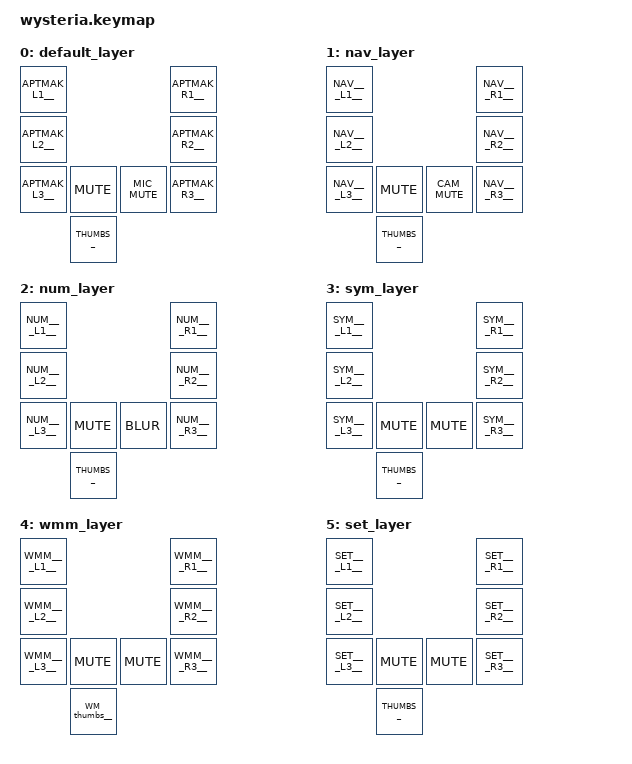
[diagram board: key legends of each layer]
#include <behaviors.dtsi>
#include <dt-bindings/zmk/keys.h>
#include "wrappers.h"
#include <dt-bindings/zmk/pointing.h>
#include <dt-bindings/zmk/bt.h>
#include <dt-bindings/zmk/outputs.h>

#include "secrets.keymap"

&nice_view_spi {
        cs-gpios = <&pro_micro 0 GPIO_ACTIVE_HIGH>;
};

#define COMBO(NAME, TERM, BINDINGS, KEYPOS) \
      combo_##NAME { \
          timeout-ms = <TERM>; \
          bindings = <BINDINGS>; \
          key-positions = <KEYPOS>; \
          layers = <0>; \
          slow-release; \
        };

/* #define U_MOUSE_SCROLL_MAX 200      // 10

#undef SCROLL_UP
#undef SCROLL_DOWN
#undef SCROLL_LEFT
#undef SCROLL_RIGHT
#define SCROLL_UP SCROLL_VERT(U_MOUSE_SCROLL_MAX)
#define SCROLL_DOWN SCROLL_VERT(-U_MOUSE_SCROLL_MAX)
#define SCROLL_LEFT SCROLL_HOR(-U_MOUSE_SCROLL_MAX)
#define SCROLL_RIGHT SCROLL_HOR(U_MOUSE_SCROLL_MAX)

*/

/* #define MACRO(NAME, BINDINGS) \ */
/*     macro_##NAME: macro_##NAME { \ */
/*                          compatible = "zmk,behavior-macro"; \ */
/*                          label = "ZM_my_macro"; \ */
/*                          #binding-cells = <0>; \ */
/*                          wait-ms = <30>; \ */
/*                          tap-ms = <40>; \ */
/*                          bindings = <BINDINGS>; \ */
/*                      }; */

&sk {
    quick-release;
    release-after-ms = <350>;
};
&sl {
    release-after-ms = <250>;
};


/ {
    behaviors {
        hm: homerow_mods {
            compatible = "zmk,behavior-hold-tap";
            label = "HOMEROW_MODS";
            #binding-cells = <2>;
            tapping-term-ms = <200>;
            quick-tap-ms = <0>;
            require-prior-idle-ms = <125>;
            flavor = "tap-preferred";
            bindings = <&kp>, <&kp>;
        };
      skq: sticky_key_quick_release {
        compatible = "zmk,behavior-sticky-key";
        label = "STICKY_KEY_QUICK_RELEASE";
        #binding-cells = <1>;
        bindings = <&kp>;
        release-after-ms = <250>;
        quick-release;
        ignore-modifiers;
      };
      wd_bspc_del: word_backspace_delete {
            compatible = "zmk,behavior-mod-morph";
            label = "WD_BACKSPACE_DELETE";
            #binding-cells = <0>;
            bindings = <&kp LA(BACKSPACE)>, <&kp LA(DELETE)>;
            mods = <(MOD_LSFT|MOD_RSFT)>;
        };
      bspc_del: backspace_delete {
            compatible = "zmk,behavior-mod-morph";
            label = "BACKSPACE_DELETE";
            #binding-cells = <0>;
            bindings = <&kp BACKSPACE>, <&kp DELETE>;
            mods = <(MOD_LSFT|MOD_RSFT)>;
        };
      dot: dot_colon {
            compatible = "zmk,behavior-mod-morph";
            label = "DOT_COLON";
            #binding-cells = <0>;
            bindings = <&kp DOT>, <&kp COLON>;
            mods = <(MOD_LSFT|MOD_RSFT)>;
            keep-mods = <(MOD_LSFT|MOD_RSFT)>;
        };
      comma: comma_scolon {
            compatible = "zmk,behavior-mod-morph";
            label = "COMMA_SCOLON";
            #binding-cells = <0>;
            bindings = <&kp COMMA>, <&kp SEMICOLON>;
            mods = <(MOD_LSFT|MOD_RSFT)>;
        };
      swap: swap_win {
            compatible = "zmk,behavior-tri-state";
            label = "SWAPPER";
            #binding-cells = <0>;
            bindings = <&kt LGUI>, <&kp TAB>, <&kt LGUI>;
            ignored-key-positions = <13>; // 13 corresponds to QWERTY F, which is my left shift
        };
      swap_app: swap_app_win {
            compatible = "zmk,behavior-tri-state";
            label = "SWAP_APP";
            #binding-cells = <0>;
            bindings = <&kt LGUI>, <&kp GRAVE>, <&kt LGUI>;
            ignored-key-positions = <13>; // 13 corresponds to QWERTY F, which is my left shift
        };
      rot_kp: behavior_sensor_rotate_kp {
            compatible = "zmk,behavior-sensor-rotate-var";
            label = "ENC_KP";
            #sensor-binding-cells = <2>;
            bindings = <&kp>, <&kp>;
        };
      rot_mwh: behavior_sensor_rotate_mwh {
            compatible = "zmk,behavior-sensor-rotate-var";
            label = "ENC_MOUSE";
            #sensor-binding-cells = <2>;
            bindings = <&msc>, <&msc>;
            tap-ms = <20>;
        };

    };

/*  0  1  2  3  4         5  6  7  8  9 */
/* 10 11 12 13 14        15 16 17 18 19 */
/* 20 21 22 23 24 25  26 27 28 29 30 31 */
/*          32 33 34  35 36 37          */

    combos {
          compatible = "zmk,combos";

            COMBO(x, 50, &kp X, 28 29)
            COMBO(z, 50, &kp Z, 22 23)
            COMBO(q, 50, &kp Q, 2 3)
            COMBO(lbkt, 50, &kp LBKT, 3 13)
            COMBO(rbkt, 50, &kp RBKT, 6 16)
            COMBO(lpar, 50, &kp LPAR, 2 12)
            COMBO(rpar, 50, &kp RPAR, 7 17)
            COMBO(caps_word_l, 50, &caps_word, 13 14)
            COMBO(caps_word_r, 50, &caps_word, 15 16)
            COMBO(lshift, 25, &sk LSHFT, 12 13)
            COMBO(rshift, 25, &sk RSHFT, 16 17)
            COMBO(emdash, 25, &kp RA(MINUS), 30 31)
            COMBO(bksp, 25, &bspc_del, 3 4)
            COMBO(ent, 25, &kp RET, 5 6)
            COMBO(htor, 50, &htor, 10 13)
            COMBO(dssr, 50, &dssr, 11 23)
            COMBO(pfv, 50, &pfv, 3 27)
            COMBO(ltab, 50, &kp TAB, 33 34)
            COMBO(rtab, 50, &kp TAB, 35 36)
    };

    conditional_layers {
        compatible = "zmk,conditional-layers";
        settings {
            if-layers = <2 4>;
            then-layer = <5>;
        };
    };

    macros {
        ZMK_MACRO(lock,
                wait-ms = <20>;
                tap-ms = <20>;
                bindings
                    = <&macro_press    &kp LGUI &kp LCTRL>
                    , <&macro_tap      &kp Q>
                    , <&macro_release  &kp LGUI &kp LCTRL>
                    , <&macro_wait_time 100>
                    , <&macro_tap      &none &kp ESC>;
                )
        ZMK_MACRO(nrc,
                wait-ms = <20>;
                tap-ms = <20>;
                bindings
                    = <&macro_press    &kp LSHFT>
                    , <&macro_tap      &kp N &kp R &kp C>
                    , <&macro_release  &kp LSHFT>;
                )
        ZMK_MACRO(mne,
                wait-ms = <20>;
                tap-ms = <20>;
                bindings
                    = <&macro_press    &kp LSHFT>
                    , <&macro_tap      &kp M &kp E &kp A &kp L>
                    , <&macro_release  &kp LSHFT>;
                )
        ZMK_MACRO(screenshot,
                wait-ms = <5>;
                tap-ms = <5>;
                bindings
                    = <&macro_press    &kp LSHFT &kp LGUI>
                    , <&macro_tap      &kp N5>
                    , <&macro_release  &kp LSHFT &kp LGUI>;
                )
        ZMK_MACRO(htor,
                wait-ms = <5>;
                tap-ms = <5>;
                bindings
                    = <&macro_press    &kp LSHFT>
                    , <&macro_tap      &kp H>
                    , <&macro_release  &kp LSHFT>
                    , <&macro_tap      &kp N2>
                    , <&macro_press    &kp LSHFT>
                    , <&macro_tap      &kp R>
                    , <&macro_release  &kp LSHFT>;
                )
        ZMK_MACRO(pfv,
                wait-ms = <5>;
                tap-ms = <5>;
                bindings
                    = <&macro_press    &kp LSHFT>
                    , <&macro_tap      &kp P>
                    , <&macro_release  &kp LSHFT>
                    , <&macro_tap      &kp F>
                    , <&macro_press    &kp LSHFT>
                    , <&macro_tap      &kp V>
                    , <&macro_release  &kp LSHFT>;
                )
        ZMK_MACRO(dssr,
                wait-ms = <5>;
                tap-ms = <5>;
                bindings
                    = <&macro_press    &kp LSHFT>
                    , <&macro_tap      &kp S &kp R>
                    , <&macro_release  &kp LSHFT>
                    , <&macro_tap      &kp FSLH>
                    , <&macro_press    &kp LSHFT>
                    , <&macro_tap      &kp D &kp S>
                    , <&macro_release  &kp LSHFT>;
                )
        ZMK_MACRO(pass,
                wait-ms = <5>;
                tap-ms = <5>;
                bindings
                    = <&macro_tap      SECRET_ONE>;
                )
        ZMK_MACRO(name,
                wait-ms = <5>;
                tap-ms = <5>;
                bindings
                    = SECRET_SIX;
                )
        ZMK_MACRO(work_email,
                wait-ms = <5>;
                tap-ms = <5>;
                bindings
                    = <&macro_tap SECRET_SEVEN>;
                )
        ZMK_MACRO(email,
                wait-ms = <5>;
                tap-ms = <5>;
                bindings
                    = <&macro_tap SECRET_TWO>;
                )
        ZMK_MACRO(phone,
                wait-ms = <5>;
                tap-ms = <5>;
                bindings
                    = <&macro_tap SECRET_THREE>;
                )
        ZMK_MACRO(so_phone,
                wait-ms = <5>;
                tap-ms = <5>;
                bindings
                    = <&macro_tap SECRET_FIVE>;
                )
        ZMK_MACRO(so_email,
                wait-ms = <5>;
                tap-ms = <5>;
                bindings
                    = <&macro_tap SECRET_FOUR>;
                )
    };

/*  0  1  2  3  4         5  6  7  8  9 */
/* 10 11 12 13 14        15 16 17 18 19 */
/* 20 21 22 23 24 25  26 27 28 29 30 31 */
/*          32 33 34  35 36 37          */

    leader_sequences {
        compatible = "zmk,leader-sequences";
        seq_pass {
            key-positions = <12 13>;
            bindings = <&pass>;
        };
        seq_name {
                key-positions = <13>;
                bindings = <&name>;
        };
        seq_work_email {
                key-positions = <16 21>;
                bindings = <&work_email>;
        };
        seq_email {
                key-positions = <21>;
                bindings = <&email>;
        };
        seq_phone {
                key-positions = <3>;
                bindings = <&phone>;
        };
        seq_so_phone {
                key-positions = <24 3>;
                bindings = <&so_phone>;
        };
        seq_so_email {
                key-positions = <24 21>;
                bindings = <&so_email>;
        };
        seq_screenshot {
                key-positions = <12 11>;
                bindings = <&screenshot>;
        };
    };

    keymap {
        compatible = "zmk,keymap";

        default_layer {
            bindings = <
                          __APTMAK_L1__           __APTMAK_R1__
                          __APTMAK_L2__           __APTMAK_R2__
                          __APTMAK_L3__ MUTE MIC_MUTE __APTMAK_R3__
                                       __THUMBS__
            >;

            /*sensor-bindings = <&inc_dec_kp C_VOL_DN C_VOL_UP &inc_dec_kp SCRL_DOWN SCRL_UP>;*/
            sensor-bindings = <&inc_dec_kp C_VOL_DN C_VOL_UP &rot_mwh MOVE_UP MOVE_DOWN>;
        };

        nav_layer {
            bindings = <
                          __NAV____L1__           __NAV____R1__
                          __NAV____L2__           __NAV____R2__
                          __NAV____L3__ MUTE CAM_MUTE __NAV____R3__
                                       __THUMBS__
            >;

            sensor-bindings = <&rot_mwh MOVE_LEFT MOVE_RIGHT &rot_mwh MOVE_RIGHT MOVE_LEFT>;
        };

        num_layer {
            bindings = <
                          __NUM____L1__           __NUM____R1__
                          __NUM____L2__           __NUM____R2__
                          __NUM____L3__ MUTE BLUR __NUM____R3__
                                       __THUMBS__
            >;

            sensor-bindings = <&rot_mwh MOVE_LEFT MOVE_RIGHT &inc_dec_kp PG_DN PG_UP>;
        };

        sym_layer {
            bindings = <
                          __SYM____L1__           __SYM____R1__
                          __SYM____L2__           __SYM____R2__
                          __SYM____L3__ MUTE MUTE __SYM____R3__
                                       __THUMBS__
            >;

            sensor-bindings = <&inc_dec_kp C_VOL_DN C_VOL_UP &inc_dec_kp PG_UP PG_DN>;
        };

        wmm_layer {
            bindings = <
                          __WMM____L1__           __WMM____R1__
                          __WMM____L2__           __WMM____R2__
                          __WMM____L3__ MUTE MUTE __WMM____R3__
                                       __WM_thumbs__
            >;

            sensor-bindings = <&inc_dec_kp C_VOL_DN C_VOL_UP &inc_dec_kp PG_DN PG_UP>;
        };

        set_layer {
            bindings = <
                          __SET____L1__           __SET____R1__
                          __SET____L2__           __SET____R2__
                          __SET____L3__ MUTE MUTE __SET____R3__
                                       __THUMBS__
            >;

            sensor-bindings = <&inc_dec_kp C_VOL_DN C_VOL_UP &inc_dec_kp PG_DN PG_UP>;
        };
    };
};
